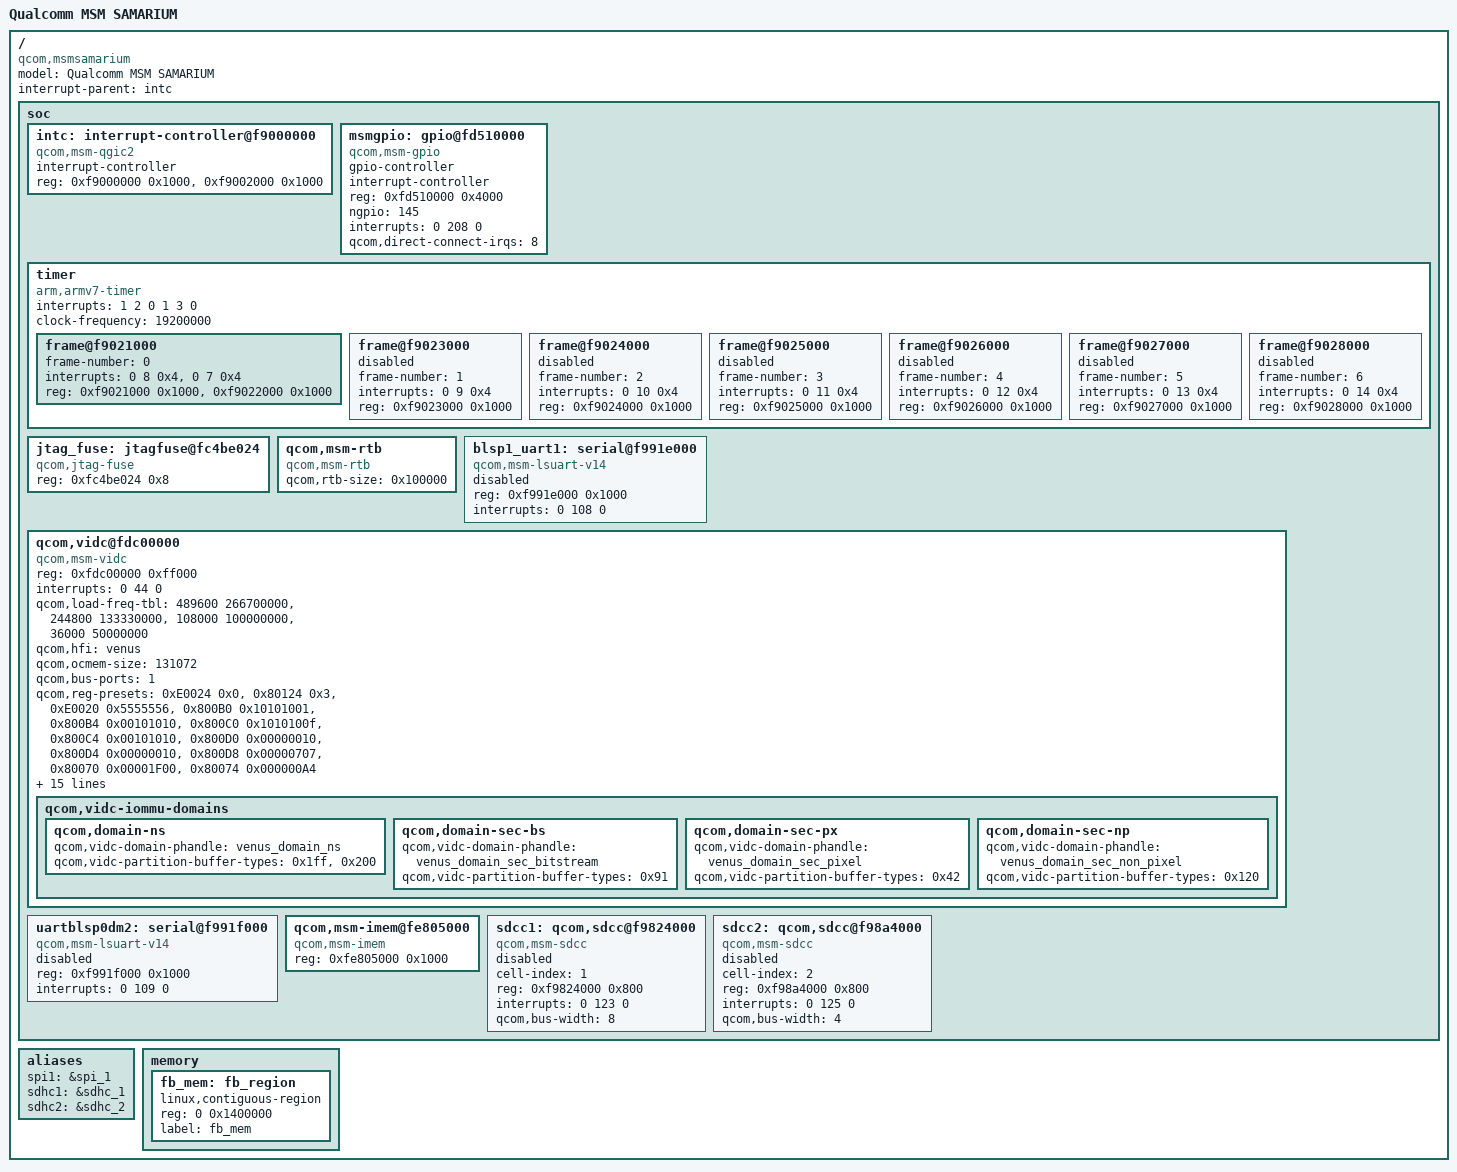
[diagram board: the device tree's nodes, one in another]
/* Copyright (c) 2013, The Linux Foundation. All rights reserved.
 *
 * This program is free software; you can redistribute it and/or modify
 * it under the terms of the GNU General Public License version 2 and
 * only version 2 as published by the Free Software Foundation.
 *
 * This program is distributed in the hope that it will be useful,
 * but WITHOUT ANY WARRANTY; without even the implied warranty of
 * MERCHANTABILITY or FITNESS FOR A PARTICULAR PURPOSE.  See the
 * GNU General Public License for more details.
 */

/include/ "skeleton.dtsi"

/ {
	model = "Qualcomm MSM SAMARIUM";
	compatible = "qcom,msmsamarium";
	interrupt-parent = <&intc>;
	soc: soc { };

	aliases {
		spi1 = &spi_1;
		sdhc1 = &sdhc_1; /* SDC1 eMMC slot */
		sdhc2 = &sdhc_2; /* SDC2 SD card slot */
	};

	memory {
		fb_mem: fb_region {
			linux,contiguous-region;
			reg = <0 0x1400000>;
			label = "fb_mem";
		};
	};
};

/include/ "msmsamarium-ion.dtsi"

&soc {
	#address-cells = <1>;
	#size-cells = <1>;
	ranges;

	intc: interrupt-controller@f9000000 {
		compatible = "qcom,msm-qgic2";
		interrupt-controller;
		#interrupt-cells = <3>;
		reg = <0xf9000000 0x1000>,
		      <0xf9002000 0x1000>;
	};

	msmgpio: gpio@fd510000 {
		compatible = "qcom,msm-gpio";
		gpio-controller;
		#gpio-cells = <2>;
		interrupt-controller;
		#interrupt-cells = <2>;
		reg = <0xfd510000 0x4000>;
		ngpio = <145>;
		interrupts = <0 208 0>;
		qcom,direct-connect-irqs = <8>;
	};

	timer {
		compatible = "arm,armv7-timer";
		interrupts = <1 2 0 1 3 0>;
		clock-frequency = <19200000>;

		frame@f9021000 {
			frame-number = <0>;
			interrupts = <0 8 0x4>,
				     <0 7 0x4>;
			reg = <0xf9021000 0x1000>,
			      <0xf9022000 0x1000>;
		};

		frame@f9023000 {
			frame-number = <1>;
			interrupts = <0 9 0x4>;
			reg = <0xf9023000 0x1000>;
			status = "disabled";
		};

		frame@f9024000 {
			frame-number = <2>;
			interrupts = <0 10 0x4>;
			reg = <0xf9024000 0x1000>;
			status = "disabled";
		};

		frame@f9025000 {
			frame-number = <3>;
			interrupts = <0 11 0x4>;
			reg = <0xf9025000 0x1000>;
			status = "disabled";
		};

		frame@f9026000 {
			frame-number = <4>;
			interrupts = <0 12 0x4>;
			reg = <0xf9026000 0x1000>;
			status = "disabled";
		};

		frame@f9027000 {
			frame-number = <5>;
			interrupts = <0 13 0x4>;
			reg = <0xf9027000 0x1000>;
			status = "disabled";
		};

		frame@f9028000 {
			frame-number = <6>;
			interrupts = <0 14 0x4>;
			reg = <0xf9028000 0x1000>;
			status = "disabled";
		};
	};

	jtag_fuse: jtagfuse@fc4be024 {
		compatible = "qcom,jtag-fuse";
		reg = <0xfc4be024 0x8>;
		reg-names = "fuse-base";
	};

	qcom,msm-rtb {
		compatible = "qcom,msm-rtb";
		qcom,rtb-size = <0x100000>; /* 1M EBI1 buffer */
	};

	blsp1_uart1: serial@f991e000 {
		compatible = "qcom,msm-lsuart-v14";
		reg = <0xf991e000 0x1000>;
		interrupts = <0 108 0>;
		status = "disabled";
	};

	qcom,vidc@fdc00000 {
		compatible = "qcom,msm-vidc";
		reg = <0xfdc00000 0xff000>;
		interrupts = <0 44 0>;
		qcom,load-freq-tbl = <489600 266700000>,
			<244800 133330000>,
			<108000 100000000>,
			<36000   50000000>;
		qcom,hfi = "venus";
		qcom,ocmem-size = <131072>; /* 128 * 1024 */
		qcom,bus-ports = <1>;
		qcom,reg-presets = <0xE0024 0x0>,
			<0x80124 0x3>,
			<0xE0020 0x5555556>,
			<0x800B0 0x10101001>,
			<0x800B4 0x00101010>,
			<0x800C0 0x1010100f>,
			<0x800C4 0x00101010>,
			<0x800D0 0x00000010>,
			<0x800D4 0x00000010>,
			<0x800D8 0x00000707>,
			<0x80070 0x00001F00>,
			<0x80074 0x000000A4>;
		qcom,enc-ocmem-ab-ib = <0 0>,
			<138000 1034000>,
			<414000 1034000>,
			<940000 1034000>,
			<1880000 2068000>;
		qcom,dec-ocmem-ab-ib = <0 0>,
			<176000 519000>,
			<456000 519000>,
			<864000 519000>,
			<1728000 1038000>;
		qcom,enc-ddr-ab-ib = <0 0>,
			<129000 142000>,
			<384000 422000>,
			<866000 953000>,
			<1732000 1906000>;
		qcom,dec-ddr-ab-ib = <0 0>,
			<103000 134000>,
			<268000 348000>,
			<505000 657000>,
			<1010000 1314000>;
		qcom,buffer-type-tz-usage-table = <0x1 0x1>,
			<0x2 0x2>,
			<0x1f0 0x3>;
		qcom,max-hw-load = <489600>; /* 1080p @ 60 */
		qcom,vidc-iommu-domains {
                qcom,domain-ns {
                        qcom,vidc-domain-phandle = <&venus_domain_ns>;
                        qcom,vidc-partition-buffer-types = <0x1ff>,
							<0x200>;
                };
                qcom,domain-sec-bs {
                        qcom,vidc-domain-phandle = <&venus_domain_sec_bitstream>;
                        qcom,vidc-partition-buffer-types = <0x91>;
                };
                qcom,domain-sec-px {
                        qcom,vidc-domain-phandle = <&venus_domain_sec_pixel>;
                        qcom,vidc-partition-buffer-types = <0x42>;
                };
                qcom,domain-sec-np {
                        qcom,vidc-domain-phandle = <&venus_domain_sec_non_pixel>;
                        qcom,vidc-partition-buffer-types = <0x120>;
                };
	    };
	};

	uartblsp0dm2: serial@f991f000 {
		compatible = "qcom,msm-lsuart-v14";
		reg = <0xf991f000 0x1000>;
		interrupts = <0 109 0>;
		status = "disabled";
	};

	qcom,msm-imem@fe805000 {
		compatible = "qcom,msm-imem";
		reg = <0xfe805000 0x1000>; /* Address and size of IMEM */
	};

	sdcc1: qcom,sdcc@f9824000 {
		cell-index = <1>; /* SDC1 eMMC slot */
		compatible = "qcom,msm-sdcc";
		reg = <0xf9824000 0x800>;
		reg-names = "core_mem";
		interrupts = <0 123 0>;
		interrupt-names = "core_irq";

		qcom,bus-width = <8>;
		status = "disabled";
	};

	sdcc2: qcom,sdcc@f98a4000 {
		cell-index = <2>; /* SDC2 SD card slot */
		compatible = "qcom,msm-sdcc";
		reg = <0xf98a4000 0x800>;
		reg-names = "core_mem";
		interrupts = <0 125 0>;
		interrupt-names = "core_irq";

		qcom,bus-width = <4>;
		status = "disabled";
	};
};
